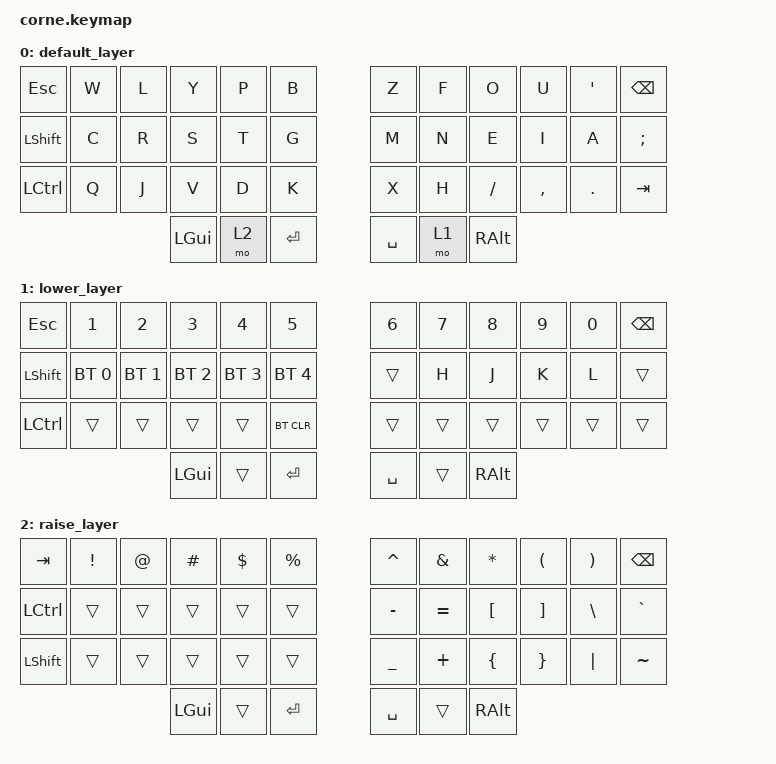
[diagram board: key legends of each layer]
/*
 * Copyright (c) 2020 The ZMK Contributors
 *
 * SPDX-License-Identifier: MIT
 */

#include <behaviors.dtsi>
#include <dt-bindings/zmk/keys.h>
#include <dt-bindings/zmk/bt.h>

/ {
        keymap {
                compatible = "zmk,keymap";

                default_layer {
// -----------------------------------------------------------------------------------------
                        bindings = <
   &kp ESC   &kp W &kp L &kp Y &kp P &kp B   &kp Z &kp F &kp O    &kp U     &kp SQT &kp BSPC
   &kp LSHFT &kp C &kp R &kp S &kp T &kp G   &kp M &kp N &kp E    &kp I     &kp A   &kp SEMI
   &kp LCTRL &kp Q &kp J &kp V &kp D &kp K   &kp X &kp H &kp FSLH &kp COMMA &kp DOT &kp TAB
                    &kp LGUI &mo 2 &kp RET   &kp SPACE &mo 1 &kp RALT
                        >;
                };
                lower_layer {
                        bindings = <
   &kp ESC    &kp N1       &kp N2       &kp N3       &kp N4       &kp N5         &kp N6    &kp N7 &kp N8 &kp N9 &kp N0 &kp BSPC
   &kp LSHIFT &bt BT_SEL 0 &bt BT_SEL 1 &bt BT_SEL 2 &bt BT_SEL 3 &bt BT_SEL 4   &trans    &kp H  &kp J &kp K   &kp L  &trans
   &kp LCTRL  &trans       &trans       &trans       &trans       &bt BT_CLR     &trans    &trans &trans  &trans  &trans &trans
                                        &kp LGUI     &trans       &kp RET      	&kp SPACE &trans &kp RALT
                        ;
                };

                raise_layer {
// -----------------------------------------------------------------------------------------
// |  TAB |  !  |  @  |  #  |  $  |  %  |   |  ^  |  &  |  *  |  (  |  )  | BSPC |
// | CTRL |     |     |     |     |     |   |  -  |  =  |  [  |  ]  |  \  |  `   |
// | SHFT |     |     |     |     |     |   |  _  |  +  |  {  |  }  | "|" |  ~   |
//                    | GUI |     | ENT |   | SPC |     | ALT |
                        bindings = <
   &kp  TAB  &kp EXCL &kp AT &kp HASH &kp DLLR &kp PRCNT   &kp CARET &kp AMPS  &kp ASTRK &kp LPAR &kp RPAR &kp BSPC
   &kp LCTRL &trans   &trans &trans   &trans   &trans      &kp MINUS &kp EQUAL &kp LBKT  &kp RBKT &kp BSLH &kp GRAVE
   &kp LSHFT &trans   &trans &trans   &trans   &trans      &kp UNDER &kp PLUS  &kp LBRC  &kp RBRC &kp PIPE &kp TILDE
                             &kp LGUI &trans   &kp RET     &kp SPACE &trans    &kp RALT
                        >;
                };
        };
};
